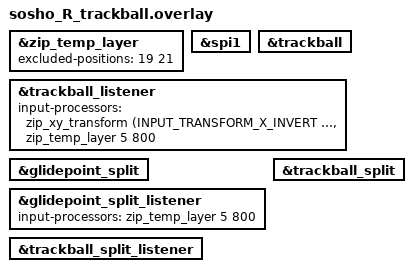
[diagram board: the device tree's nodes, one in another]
#include "sosho_R.dtsi"

&zip_temp_layer {
	// JとLを押してもマウスレイヤーを維持する
    excluded-positions = <19 21>;
};

/*
glidepoint_listnerは右手のトラックパッド
glidepoint_split_listenerとtrackball_split_listenerは
左手のトラックパッドとトラックボールの受けです。
ここにinput-processorというオプションをつけると、いろんな動きができます。
代表的なものを書いておきます。

・ポインタの移動を早くしたいとき
&zip_xy_scalerを使います。
分子 分母の順に数字を指定します。2 1なら2倍です。
input-processors = <&zip_xy_scaler 2 1>;

・スクロールを割り当てたいとき
zip_xy_to_scroll_mapperを使います。
ポインティングデバイスの動きをスクロールに変換してくれます。
input-processors = <&zip_xy_to_scroll_mapper>;

・移動を反転したいとき
zip_xy_transformを使います。
これは&trackball_listenerで実際に使っています。

これらオプションは複数併記することもできます。
input-processors = <&zip_xy_scaler 1 3>,<&zip_xy_to_scroll_mapper>;

詳しい情報はzmkのドキュメントを確認してください。
https://zmk.dev/docs/keymaps/input-processors
*/

&spi1 { status = "okay"; };
&trackball { status = "okay"; };
&trackball_listener {
	status = "okay";
	input-processors = <
		&zip_xy_transform (INPUT_TRANSFORM_X_INVERT | INPUT_TRANSFORM_Y_INVERT)
		&zip_temp_layer 5 800
	>;
};

&glidepoint_split { status = "okay"; };
&glidepoint_split_listener {
    status = "okay";
    // 左側トラックパッドにもオートマウスレイヤーを適用する
    input-processors = <&zip_temp_layer 5 800>;
};

&trackball_split { status = "okay"; };
&trackball_split_listener {
	status = "okay"; 
	//input-processors = <&zip_xy_to_scroll_mapper>;
};
